VERSION ""

NS_ :

    I/O_
    SIGNAL_
    SIGNAL_TYPE_
    UNIT_

BS_:

BU_: ECU1 TestTool

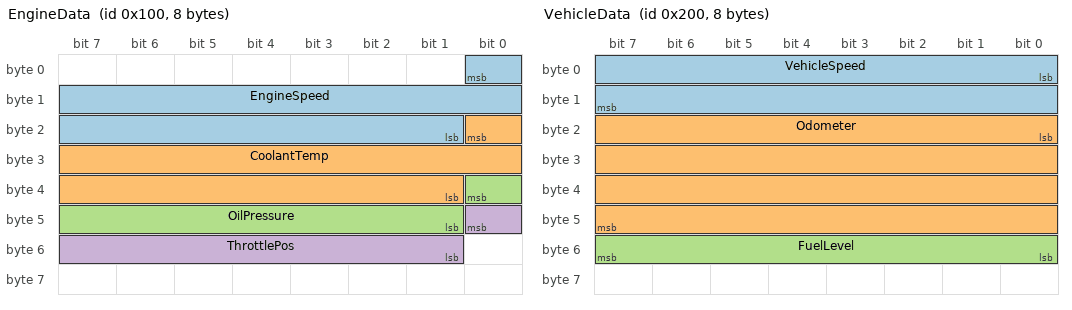
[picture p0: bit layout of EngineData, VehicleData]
BO_ 256 EngineData: 8 ECU1
 SG_ EngineSpeed : 0|16@0+ (1,0) [0|8000] "rpm" TestTool
 SG_ CoolantTemp : 16|16@0+ (0.1,-40) [-40|215] "degC" TestTool
 SG_ OilPressure : 32|8@0+ (0.5,0) [0|100] "bar" TestTool
 SG_ ThrottlePos : 40|8@0+ (0.4,0) [0|100] "%" TestTool

BO_ 512 VehicleData: 8 ECU1
 SG_ VehicleSpeed : 0|16@1+ (0.01,0) [0|300] "km/h" TestTool
 SG_ Odometer : 16|32@1+ (0.1,0) [0|999999] "km" TestTool
 SG_ FuelLevel : 48|8@1+ (0.5,0) [0|100] "%" TestTool

BO_ 768 BrakeData: 4 ECU1
 SG_ BrakePressure : 0|16@0+ (0.01,0) [0|100] "bar" TestTool
 SG_ BrakeSwitch : 16|1@0+ (1,0) [0|1] "" TestTool
